# R7FA0E107 register map
Vendor: Renesas Electronics Corporation; Series: RA0; File version: 1.10.00
CPU: CM23 r1p0, little endian, no MPU, no FPU, VTOR, 2 interrupt priority bits, 64 interrupts
Registers are 16-bit, read-write, reset 0x0 unless marked. A register's access mark holds for its fields unless they carry their own. Offsets are from the block's base; [hi:lo] are bit positions; {n}, {i} and the like mark numbered series.

## PORT2 — Port 2 Control
Base 0x400A0040
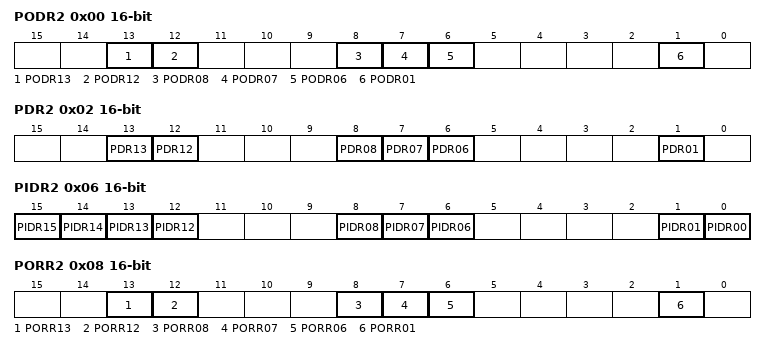
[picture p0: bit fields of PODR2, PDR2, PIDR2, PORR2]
0x00 PODR2 — Port 2 Output Data Register
  [all] fields
    0=Low output; 1=High output
  [13] PODR13 — P213 Output Data
  [12] PODR12 — P212 Output Data
  [8] PODR08 — P208 Output Data
  [7] PODR07 — P207 Output Data
  [6] PODR06 — P206 Output Data
  [1] PODR01 — P201 Output Data
0x02 PDR2 — Port 2 Direction Register
  [all] fields
    0=Output 0; 1=Output 1
  [13] PDR13 — P213 Direction
  [12] PDR12 — P212 Direction
  [8] PDR08 — P208 Direction
  [7] PDR07 — P207 Direction
  [6] PDR06 — P206 Direction
  [1] PDR01 — P201 Direction
0x06 PIDR2 ro (reset mask 0xE3C) — Port 2 State Register
  [all] fields
    0=Low level; 1=High level
  [n] PIDR{n} (n=12..15) — P{n+200} State
  [8] PIDR08 — P208 State
  [7] PIDR07 — P207 State
  [6] PIDR06 — P206 State
  [1] PIDR01 — P201 State
  [0] PIDR00 — P200 State
0x08 PORR2 wo — Port 2 Output Reset Register
  [all] fields
    0=No effect on output; 1=Low output
  [13] PORR13 — P213 Output Reset
  [12] PORR12 — P212 Output Reset
  [8] PORR08 — P208 Output Reset
  [7] PORR07 — P207 Output Reset
  [6] PORR06 — P206 Output Reset
  [1] PORR01 — P201 Output Reset
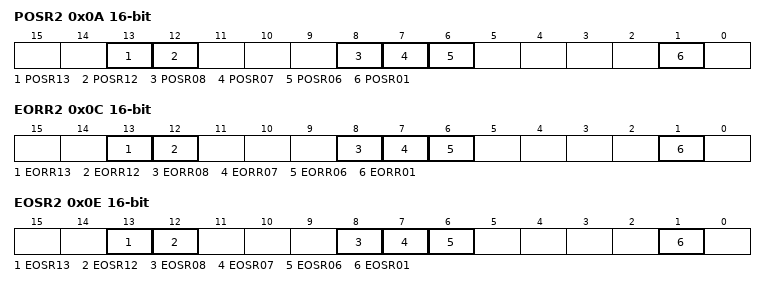
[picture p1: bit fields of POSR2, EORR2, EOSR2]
0x0A POSR2 wo — Port 2 Output Set Register
  [all] fields
    0=No effect on output; 1=High output
  [13] POSR13 — P213 Output Set
  [12] POSR12 — P212 Output Set
  [8] POSR08 — P208 Output Set
  [7] POSR07 — P207 Output Set
  [6] POSR06 — P206 Output Set
  [1] POSR01 — P201 Output Set
0x0C EORR2 — Port 2 Event Output Reset Register
  [all] fields
    0=No effect on output; 1=Low output
  [13] EORR13 — P213 Event Output Reset
  [12] EORR12 — P212 Event Output Reset
  [8] EORR08 — P208 Event Output Reset
  [7] EORR07 — P207 Event Output Reset
  [6] EORR06 — P206 Event Output Reset
  [1] EORR01 — P201 Event Output Reset
0x0E EOSR2 — Port 2 Event Output Set Register
  [all] fields
    0=No effect on output; 1=High output
  [13] EOSR13 — P213 Event Output Set
  [12] EOSR12 — P212 Event Output Set
  [8] EOSR08 — P208 Event Output Set
  [7] EOSR07 — P207 Event Output Set
  [6] EOSR06 — P206 Event Output Set
  [1] EOSR01 — P201 Event Output Set

## PORT3 — Port 3 Control
Base 0x400A0060
0x00 PODR3 — Port 3 Output Data Register
  [0] PODR00 — P300 Output Data
    0=Low output; 1=High output
0x02 PDR3 — Port 3 Direction Register
  [0] PDR00 — P300 Direction
    0=Output 0; 1=Output 1
0x06 PIDR3 ro (reset mask 0xFFFE) — Port 3 State Register
  [0] PIDR00 — P300 State
    0=Low level; 1=High level
0x08 PORR3 wo — Port 3 Output Reset Register
  [0] PORR00 — P300 Output Reset
    0=No effect on output; 1=Low output
0x0A POSR3 wo — Port 3 Output Set Register
  [0] POSR00 — P300 Output Set
    0=No effect on output; 1=High output

## PORT4 — Port 4 Control
Base 0x400A0080
0x00 PODR4 — Port 4 Output Data Register
  [7] PODR07 — P407 Output Data
    0=Low output; 1=High output
0x02 PDR4 — Port 4 Direction Register
  [7] PDR07 — P407 Direction
    0=Output 0; 1=Output 1
0x06 PIDR4 ro (reset mask 0xFF7F) — Port 4 State Register
  [7] PIDR07 — P407 State
    0=Low level; 1=High level
0x08 PORR4 wo — Port 4 Output Reset Register
  [7] PORR07 — P407 Output Reset
    0=No effect on output; 1=Low output
0x0A POSR4 wo — Port 4 Output Set Register
  [7] POSR07 — P407 Output Set
    0=No effect on output; 1=High output

## PORT9 — Port 9 Control
Base 0x400A0120
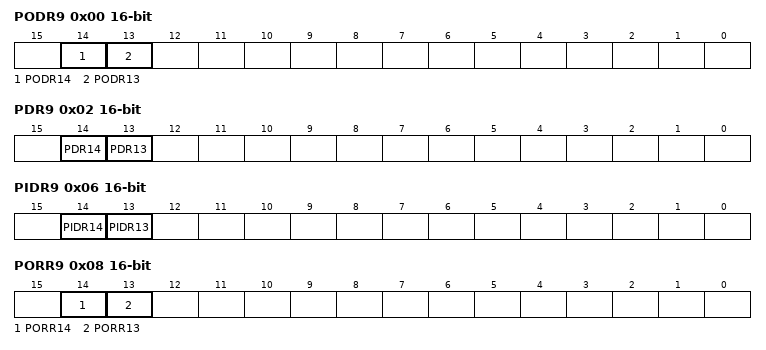
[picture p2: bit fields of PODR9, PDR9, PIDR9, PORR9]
0x00 PODR9 — Port 9 Output Data Register
  [14] PODR14 — P914 Output Data
    0=Low output; 1=High output
  [13] PODR13 — P913 Output Data
    0=Low output; 1=High output
0x02 PDR9 — Port 9 Direction Register
  [14] PDR14 — P914 Direction
    0=Output 0; 1=Output 1
  [13] PDR13 — P913 Direction
    0=Output 0; 1=Output 1
0x06 PIDR9 ro (reset mask 0x9FFF) — Port 9 State Register
  [14] PIDR14 — P914 State
    0=Low level; 1=High level
  [13] PIDR13 — P913 State
    0=Low level; 1=High level
0x08 PORR9 wo — Port 9 Output Reset Register
  [14] PORR14 — P914 Output Reset
    0=No effect on output; 1=Low output
  [13] PORR13 — P913 Output Reset
    0=No effect on output; 1=Low output
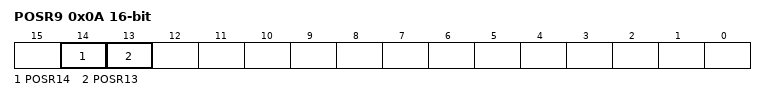
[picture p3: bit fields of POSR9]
0x0A POSR9 wo — Port 9 Output Set Register
  [14] POSR14 — P914 Output Set
    0=No effect on output; 1=High output
  [13] POSR13 — P913 Output Set
    0=No effect on output; 1=High output

## Notices in the file
This software is supplied by Renesas Electronics Corporation and is only intended for
use with Renesas products. No other uses are authorized. This software is owned by
Renesas Electronics Corporation and is protected under all applicable laws, including
copyright laws.
THIS SOFTWARE IS PROVIDED "AS IS" AND RENESAS MAKES NO WARRANTIES REGARDING
THIS SOFTWARE, WHETHER EXPRESS, IMPLIED OR STATUTORY, INCLUDING BUT NOT LIMITED TO
WARRANTIES OF MERCHANTABILITY, FITNESS FOR A PARTICULAR PURPOSE AND NON-INFRINGEMENT.
ALL SUCH WARRANTIES ARE EXPRESSLY DISCLAIMED. TO THE MAXIMUM EXTENT PERMITTED NOT
PROHIBITED BY LAW, NEITHER RENESAS ELECTRONICS CORPORATION NOR ANY OF ITS AFFILIATED
COMPANIES SHALL BE LIABLE FOR ANY DIRECT, INDIRECT, SPECIAL, INCIDENTAL OR CONSEQUENTIAL
DAMAGES FOR ANY REASON RELATED TO THIS SOFTWARE, EVEN IF RENESAS OR ITS AFFILIATES HAVE
BEEN ADVISED OF THE POSSIBILITY OF SUCH DAMAGES.
Renesas reserves the right, without notice, to make changes to this software and to
discontinue the availability of this software. By using this software, you agree to
the additional terms and conditions found by accessing the following link:
http://www.renesas.com/disclaimer
